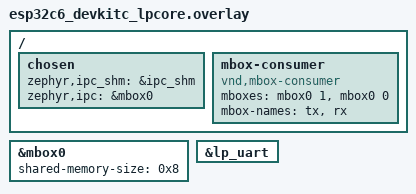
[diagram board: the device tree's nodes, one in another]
/*
 * Copyright (c) 2026 Espressif Systems (Shanghai) Co., Ltd.
 *
 * SPDX-License-Identifier: Apache-2.0
 */

/ {
	chosen {
		zephyr,ipc_shm = &ipc_shm;
		zephyr,ipc = &mbox0;
	};

	mbox-consumer {
		compatible = "vnd,mbox-consumer";
		mboxes = <&mbox0 1>, <&mbox0 0>;
		mbox-names = "tx", "rx";
	};
};

&mbox0 {
	shared-memory-size = <0x8>;
};

&lp_uart {
	status = "okay";
};
